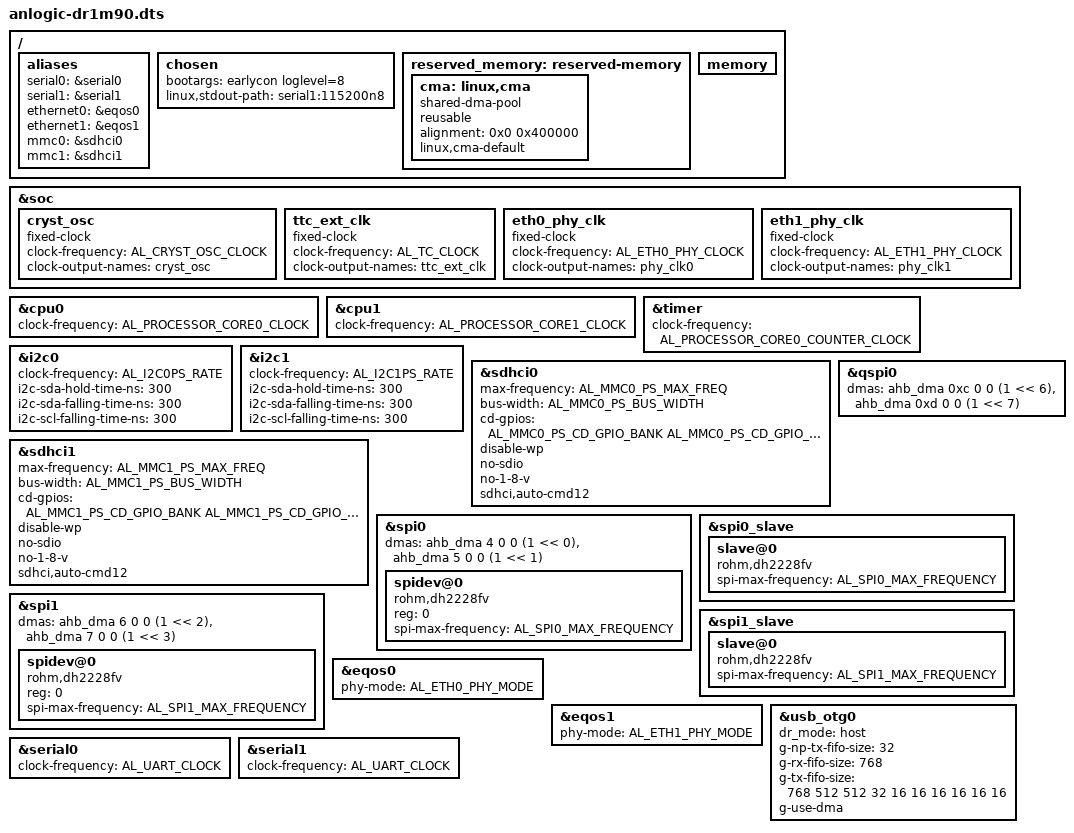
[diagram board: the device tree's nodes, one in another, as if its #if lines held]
// SPDX-License-Identifier: (GPL-2.0+ OR MIT)

/dts-v1/;
#include "anlogic-dr1m90.dtsi"
#include "anlogic-dr1m90-plat.h"
#include "anlogic-dr1m90-settings.h"

/ {
	aliases {
		serial0 = &serial0;
		serial1 = &serial1;
		ethernet0 = &eqos0;
		ethernet1 = &eqos1;
		mmc0 = &sdhci0;
		mmc1 = &sdhci1;
	};

	chosen: chosen {
		bootargs = "earlycon loglevel=8";
		linux,stdout-path = "serial1:115200n8";
	};

	reserved_memory: reserved-memory {
		#address-cells = <2>;
		#size-cells = <2>;
		ranges;

		cma: linux,cma {
			compatible = "shared-dma-pool";
			reusable;
			alignment = <0x0 0x400000>;
			linux,cma-default;
		};
	};

	memory: memory {
		device_type = "memory";
	};
};

&soc {
	cryst_osc: cryst_osc {
		#clock-cells = <0>;
		compatible = "fixed-clock";
		clock-frequency = <AL_CRYST_OSC_CLOCK>;
		clock-output-names = "cryst_osc";
	};

	ttc_ext_clk: ttc_ext_clk {
		#clock-cells = <0>;
		compatible = "fixed-clock";
		clock-frequency = <AL_TC_CLOCK>;
		clock-output-names = "ttc_ext_clk";
	};

	eth0_phy_clk: eth0_phy_clk {
		#clock-cells = <0>;
		compatible = "fixed-clock";
		clock-frequency = <AL_ETH0_PHY_CLOCK>;
		clock-output-names = "phy_clk0";
	};

	eth1_phy_clk: eth1_phy_clk {
		#clock-cells = <0>;
		compatible = "fixed-clock";
		clock-frequency = <AL_ETH1_PHY_CLOCK>;
		clock-output-names = "phy_clk1";
	};
};

&cpu0 {
	clock-frequency = <AL_PROCESSOR_CORE0_CLOCK>;
};

&cpu1 {
	clock-frequency = <AL_PROCESSOR_CORE1_CLOCK>;
};

&timer {
	clock-frequency = <AL_PROCESSOR_CORE0_COUNTER_CLOCK>;
};

&i2c0 {
	clock-frequency = <AL_I2C0PS_RATE>;
	i2c-sda-hold-time-ns = <300>;
	i2c-sda-falling-time-ns = <300>;
	i2c-scl-falling-time-ns = <300>;
};

&i2c1 {
	clock-frequency = <AL_I2C1PS_RATE>;
	i2c-sda-hold-time-ns = <300>;
	i2c-sda-falling-time-ns = <300>;
	i2c-scl-falling-time-ns = <300>;
};

&sdhci0 {
	max-frequency = <AL_MMC0_PS_MAX_FREQ>;
	bus-width = <AL_MMC0_PS_BUS_WIDTH>;
	#if AL_MMC0_PS_CD_ENABLE
	cd-gpios=<&AL_MMC0_PS_CD_GPIO_BANK AL_MMC0_PS_CD_GPIO_PORT GPIO_ACTIVE_LOW>;
	#elif defined(ANLSDK_MMC0_CD_GPIO_ENABLE)
	cd-gpios=<&ANLSDK_MMC0_CD_GPIO_PORT ANLSDK_MMC0_CD_GPIO_ID ANLSDK_MMC0_CD_GPIO_ACTIVE_LEVEL>;
	#else
	non-removable;
	broken-cd;
	#endif
	disable-wp;
	no-sdio;
	no-1-8-v;
	sdhci,auto-cmd12;
};

&sdhci1 {
	max-frequency = <AL_MMC1_PS_MAX_FREQ>;
	bus-width = <AL_MMC1_PS_BUS_WIDTH>;
	#if AL_MMC1_PS_CD_ENABLE
	cd-gpios=<&AL_MMC1_PS_CD_GPIO_BANK AL_MMC1_PS_CD_GPIO_PORT GPIO_ACTIVE_LOW>;
	#elif defined(ANLSDK_MMC1_CD_GPIO_ENABLE)
	cd-gpios=<&ANLSDK_MMC1_CD_GPIO_PORT ANLSDK_MMC1_CD_GPIO_ID ANLSDK_MMC1_CD_GPIO_ACTIVE_LEVEL>;
	#else
	non-removable;
	broken-cd;
	#endif
	disable-wp;
	no-sdio;
	no-1-8-v;
	sdhci,auto-cmd12;
};

&qspi0 {
	dmas = <&ahb_dma 0xc 0 0 (1 << 6)>,
			<&ahb_dma 0xd 0 0 (1 << 7)>;
	dma-names = "tx", "rx";
};

&spi0 {
	dmas = <&ahb_dma 4 0 0 (1 << 0)>,
			<&ahb_dma 5 0 0 (1 << 1)>;
	dma-names = "tx", "rx";
	spidev@0 {
		compatible = "rohm,dh2228fv";
		reg = <0>;
		spi-max-frequency = <AL_SPI0_MAX_FREQUENCY>;
	};
};

&spi0_slave {
	slave@0 {
		compatible = "rohm,dh2228fv";
		spi-max-frequency = <AL_SPI0_MAX_FREQUENCY>;
	};
};

&spi1 {
	dmas = <&ahb_dma 6 0 0 (1 << 2)>,
			<&ahb_dma 7 0 0 (1 << 3)>;
	dma-names = "tx", "rx";
	spidev@0 {
		compatible = "rohm,dh2228fv";
		reg = <0>;
		spi-max-frequency = <AL_SPI1_MAX_FREQUENCY>;
	};
};

&spi1_slave {
	slave@0 {
		compatible = "rohm,dh2228fv";
		spi-max-frequency = <AL_SPI1_MAX_FREQUENCY>;
	};
};

&eqos0 {
	phy-mode = AL_ETH0_PHY_MODE;
};

&eqos1 {
	phy-mode = AL_ETH1_PHY_MODE;
};

&usb_otg0 {
	dr_mode = "host";
	g-np-tx-fifo-size = <32>;
	g-rx-fifo-size = <768>;
	g-tx-fifo-size = <768 512 512 32 16 16 16 16 16 16>;
	g-use-dma;
};

&serial0 {
	clock-frequency = <AL_UART_CLOCK>;
};

&serial1 {
	clock-frequency = <AL_UART_CLOCK>;
};
